# DA1470x register map
Vendor: Dialog; Series: DA1470x; File version: 1.2
CPU: CM33 r0p2, little endian, MPU, FPU, DSP, VTOR, 4 interrupt priority bits
Registers are 32-bit, read-write, reset 0x0 unless marked. A register's access mark holds for its fields unless they carry their own. Offsets are from the block's base; [hi:lo] are bit positions; {n}, {i} and the like mark numbered series.

## I3C — I3C registers
Base 0x50020C00
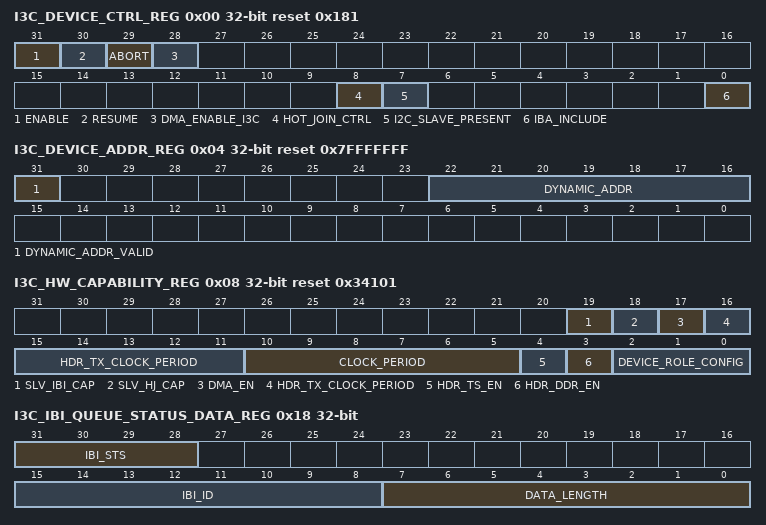
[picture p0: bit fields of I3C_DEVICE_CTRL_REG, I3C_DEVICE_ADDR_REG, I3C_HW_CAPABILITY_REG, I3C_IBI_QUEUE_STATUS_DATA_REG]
0x00 I3C_DEVICE_CTRL_REG reset 0x181 (reset mask 0x7FFFFFFF) — Device Control Register
  [31] ENABLE — Controls whether or not DWC_mipi_i3c is enabled. 1: Enables the DWC_mipi_i3c controller. 0: Disables the DWC_mipi_i3c controller. In Master mode of operation, software can Disable DWC_mipi_i3c while it is active. However, the controller may not get Disabled immediately and will be 'Disabled' after commands in the Command queue (if any) are executed leading to a STOP condition on the bus and Master FSM is in IDLE state (as indicated by PRESENT_STATE Register).
  [30] RESUME — DWC_mipi_i3c Resume. This bit is used to resume the Controller after it goes to Halt state. In the master mode of operation the controller goes to the halt state (as indicated in PRESENT_STATE Register) due to any type of error in the transfer (the type of error is indicated by ERR_STATUS field in the RESPONSE_QUEUE_PORT register). After the controller has gone to halt state, the application has to write 1'b1 to this bit to resume the controller. This bit is auto-cleared once the controller resumes the transfers by initiating the next command.
  [29] ABORT — DWC_mipi_i3c Abort. This bit is used in master mode of operation. This bit allows the controller to relinquish the I3C Bus before completing the issued transfer. In response to an ABORT request, the controller issues the STOP condition after the complete data byte is transferred or received. This bit is auto-cleared once the transfer is aborted and controller issues a 'Transfer Abort' interrupt.
  [28] DMA_ENABLE_I3C — DMA Handshake Interface Enable. This bit is used to enable or disable the DMA Handshaking interface and is applicable to both Master and Slave mode of operation. 1: Enables the DMA handshake control to interact with external DMA. 0: The DMA handshake control has no significance.
  [8] HOT_JOIN_CTRL — Hot-Join Ack/Nack Control This bit is used in master mode of operation. This bit acts as global control to ACK/NACK the Hot-Join Request from the devices. The DWC_mipi_i3c Master will ACK/NACK the Hot-Join request from other devices connected on the I3C Bus, based on programming of this bit. 0: ACK the Hot-join request. 1: NACK and send broadcast CCC to disable Hot-join. Values: 0x0 (DISABLED): Ack Hot-Join requests 0x1 (ENABLED): Nack and auto-disable Hot-Join request
  [7] I2C_SLAVE_PRESENT — I2C Slave Present This bit is used in master mode of operation. This Bit indicates whether any Legacy I2C Devices are present in the system. In HDR mode, this field is used to select TSL over TSP in mixed bus configuration. Values: 0x0 (DISABLED): I2C Slave not present 0x1 (ENABLED): I2C Slave present
  [0] IBA_INCLUDE — I3C Broadcast Address include. This bit is used in master mode of operation. This bit is used to include I3C broadcast address (0x7E) for private transfer. Note: If I3C broadcast address is not included for the private transfers, In-band Interrupts (IBI) driven from Slaves may not win address arbitration. Hence, the IBIs will get delayed. Values: 0x0 (NOT_INCLUDED): I3C Broadcast Address is not included for Private Transfers 0x1 (INCLUDED): I3C Broadcast Address is included for Private Transfers
0x04 I3C_DEVICE_ADDR_REG reset 0x7FFFFFFF (reset mask 0x7FFFFFFF) — Device Address Register
  [31] DYNAMIC_ADDR_VALID — Dynamic Address Valid This bit is used to control whether the DYNAMIC_ADDR is valid or not. In I3C Main Master mode, the user sets this bit to 1 as it self-assigns its dynamic address. In all other operation modes, the Controller sets this bit to 1 when Main Master assigns the Dynamic address during ENTDAA or SETDASA mechanism. Values: 0x0 (INVALID): Dynamic Address is invalid 0x1 (VALID): Dynamic Address is valid
  [22:16] DYNAMIC_ADDR — Device Dynamic Address. This field is used to program the Device Dynamic Address. The Controller uses this address for I3C transfers. In Main Master mode, the user/application has to program the Dynamic Address through the Slave interface as it self-assigns its Dynamic Address. In all other modes, the Main Master assigns this address during ENTDAA or SETDASA mechanism.
0x08 I3C_HW_CAPABILITY_REG reset 0x34101 — Hardware Capability register
  [19] SLV_IBI_CAP ro — Reflects the IC_SLV_IBI Configurable Parameter. Specifies slave's capability to initiate slave interrupt requests.
  [18] SLV_HJ_CAP ro — Reflects the IC_SLV_HJ Configurable Parameter. Specifies slave's capability to initiate Hot-join request.
  [17] DMA_EN ro — Reflects the IC_HAS_DMA Configurable Parameter. Specifies whether controller is configured to have DMA handshaking interface.
  [16:11] HDR_TX_CLOCK_PERIOD ro — Reflects the IC_HDR_TX_CLK_PERIOD Configurable Parameter.
  [10:5] CLOCK_PERIOD ro — Reflects the IC_CLK_PERIOD Configurable Parameter
  [4] HDR_TS_EN ro — Reflects the IC_SPEED_HDR_TS Configurable Parameter. Specifies the Controllers capability to perform HDR-TS transfers. 0 : HDR-TS not supported 1 : HDR-TS supported
  [3] HDR_DDR_EN ro — Reflects the IC_SPEED_HDR_DDR Configurable Parameter. Specifies the Controllers capability to perform HDR-DDR transfers. 0 : HDR-DDR not supported 1 : HDR-DDR supported
  [2:0] DEVICE_ROLE_CONFIG ro — Reflects the IC_DEVICE_ROLE Configurable Parameter. Specifies the configured role of DWC_mipi_i3c controller 1 : Master Only 2 : Programmable Master-Slave 3 : Secondary Master 4 : Slave Only
0x0C I3C_COMMAND_QUEUE_PORT_REG (reset mask 0x7FFFFFFF) — COMMAND_QUEUE_PORT
  [31:0] COMMAND wo — 32 bit command
0x10 I3C_RESPONSE_QUEUE_PORT_REG (reset mask 0x7FFFFFFF) — RESPONSE_QUEUE_PORT
  [31:0] RESPONSE ro — 32 bit Response
0x14 I3C_RX_TX_DATA_PORT_REG (reset mask 0x7FFFFFFF) — Receive and Transmit Data Port Register
  [31:0] RX_TX_DATA_PORT — Receive and Transmit Data Port. (Merged in Doxbox) The Receive data port is mapped to the Rx-Data Buffer. The Receive data is always packed in 4-byte aligned data words and stored in the Rx-Data Buffer. If the command length is not aligned to the 4-bytes, then the additional data bytes have to be ignored.
0x18 I3C_IBI_QUEUE_STATUS_DATA_REG (reset mask 0x7FFFFFFF) — In-Band Interrupt Queue Status and Data Register
  [31:28] IBI_STS ro — IBI Received Status. Defines the master response for IBI received. 4'b0xxx: Responded with ACK 4'b1xxx: Responded with NACK Others : RESERVED
  [15:8] IBI_ID ro — IBI Identifier. The byte received after START which includes the address and the R/W bit. Device address and R/W bit in case of Slave Interrupt or Master Request. Hot-Join ID and R/W bit in case of Hot-Join IBI.
  [7:0] DATA_LENGTH ro — In-Band Interrupt data length. This field represents the length of data received along with the IBI, in bytes.
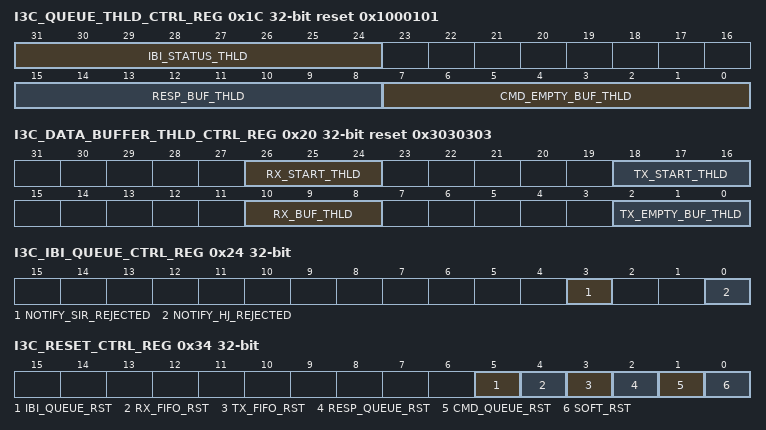
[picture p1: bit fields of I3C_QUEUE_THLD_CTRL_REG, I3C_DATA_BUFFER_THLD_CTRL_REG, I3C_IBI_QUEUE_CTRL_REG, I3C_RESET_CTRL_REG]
0x1C I3C_QUEUE_THLD_CTRL_REG reset 0x1000101 (reset mask 0x7FFFFFFF) — Queue Threshold Control Register
  [31:24] IBI_STATUS_THLD — In-Band Interrupt Status Threshold Value. Every In Band Interrupt received (with or without data) by I3C controller generates an IBI status. This field controls the number of IBI status entries (or greater) in the IBI queue that trigger the IBI_THLD_STAT interrupt. The valid range is 0 to 7. The software shall program only valid values. A value of 0 sets the threshold for 1 entry, and a value of N sets the threshold for N+1 entries.
  [15:8] RESP_BUF_THLD — Response Buffer Threshold Value. Controls the number of entries (or greater) in the Response Queue that trigger the RESP_READY_STAT_INTR interrupt. The valid range is 0 to 3. The software shall program only valid values. A value of 0 sets the threshold for 1 entry, and a value of N sets the threshold for N+1 entries.
  [7:0] CMD_EMPTY_BUF_THLD — Command Buffer Empty Threshold Value. Controls the number of empty locations (or greater) in the Command Queue that trigger CMD_QUEUE_READY_STAT interrupt. The valid range is 0 to 7. The software shall program only valid values. Value of N ranging from 1 to 7 sets the threshold to N empty locations and a value of 0 sets the threshold to indicate that the queue is completely empty.
0x20 I3C_DATA_BUFFER_THLD_CTRL_REG reset 0x3030303 — Data Buffer Threshold Control Register
  [26:24] RX_START_THLD — Receive Start Threshold Value. In master mode of operation when the controller is set up to initiate a read transfer, it waits until either one of the conditions are met before it initiates the read transfer on the I3C Interface. Data length (as specified in the command) number of locations are empty in the Receive FIFO. Threshold number of locations (or more) are empty in the Receive FIFO. The supported values for RX_START_THLD are: 000 - 1 001 - 4 010 - 8 011 - 16 100 - 32 101 - 64
  [18:16] TX_START_THLD — Transfer Start Threshold Value. In master mode of operation when the controller is set up to initiate a write transfer, it waits until either one of the following conditions are met before it initiates the write transfer on the I3C Interface. Data length (as specified in the command) number of locations are filled in the Transmit FIFO Threshold number of entries (or more) are available in the Transmit FIFO The supported values for TX_START_THLD are: 000: 1 001: 4 010: 8 011: 16 100: 32 101: 64
  [10:8] RX_BUF_THLD — Receive Buffer Threshold Value. This field controls the number of entries (or above) in the Receive FIFO that trigger the RX_THLD_STAT interrupt. If the programmed value is greater than the buffer depth, then threshold will be set to 32. The supported values for RX_BUF_THLD are 000: 1 001: 4 010: 8 011: 16 100: 32 101: 64
  [2:0] TX_EMPTY_BUF_THLD — Transmit Buffer Threshold Value. This field controls the number of empty locations (or above) in the Transmit FIFO that trigger the TX_THLD_STAT interrupt. If the programmed value is greater than the buffer depth, then threshold will be set to 32. The supported values for TX_BUF_THLD are 000: 1 001: 4 010: 8 011: 16 100: 32 101: 64
0x24 I3C_IBI_QUEUE_CTRL_REG — IBI Queue Control Register
  [3] NOTIFY_SIR_REJECTED — Notify Rejected Slave Interrupt Request Control. This bit is used to suppress reporting to the application about SIR request rejected. 0: Suppress passing the IBI Status to the IBI FIFO (hence not notifying the application) when a Slave Interrupt Request is NACKed and auto-disabled based on the IBI_SIR_REQ_REJECT Register. 1: Writes IBI Status to the IBI FIFO (hence notifying the application) when a Slave Interrupt Request is NACKed and auto-disabled based on the IBI_SIR_REQ_REJECT Register. Values: 0x0 (DISABLED): Notify SIR Rejected Disable 0x1 (ENABLED): Notify SIR Rejected Enable
  [0] NOTIFY_HJ_REJECTED — Notify Rejected Hot-Join Control. This bit is used to suppress reporting to the application about Hot-Join request rejected (NACK and Auto Disable). 0: Suppress passing the IBI Status to the IBI FIFO (hence not notifying the application) when a HJ Request is NACKed and auto-disabled based on the DEVICE_CTRL.HOT_JOIN_CTRL. 1: Writes IBI Status to the IBI FIFO (hence notifying the application) when a HJ Request is NACKed and auto-disabled based on the DEVICE_CTRL.HOT_JOIN_CTRL. Values: 0x0 (DISABLED): Notify Hot-Join Rejected Disable 0x1 (ENABLED): Notify Hot-Join Rejected Enable
0x30 I3C_IBI_SIR_REQ_REJECT_REG (reset mask 0x7FFFFFFF) — IBI SIR Request Rejection Control Register
  [31:0] SIR_REQ_REJECT — In-band Slave Interrupt Request Reject. The application of the DWC_mipi_i3c can decide whether to send ACK or NACK for a Slave request received from any I3C device. A device specific response control bit is provided to select the response option. Master will ACK/NACK the Master Request based on programming of control bit, corresponding to the interrupting device. 0 - ACK the SIR Request 1 - NACK and send directed auto disable CCC
0x34 I3C_RESET_CTRL_REG — Reset Control Register
  [5] IBI_QUEUE_RST — IBI Queue Software Reset. This bit is only used in master mode of operation. Write 1'b1 to this bit to exercise IBI Queue reset This bit will be cleared automatically once the IBI Queue reset is completed.
  [4] RX_FIFO_RST — Receive Buffer Software Reset. Write 1'b1 to this bit to exercise Receive Buffer reset. This bit will be cleared automatically once the Receive buffer reset is completed.
  [3] TX_FIFO_RST — Transmit Buffer Software Reset. Write 1'b1 to this bit to exercise Transmit Buffer reset. This bit will be cleared automatically once the Transmit Buffer reset is completed.
  [2] RESP_QUEUE_RST — Response Queue Software Reset. Write 1'b1 to this bit to exercise Response Queue reset. This bit will be cleared automatically once the Response Queue reset is completed.
  [1] CMD_QUEUE_RST — Command Queue Software Reset. Write 1'b1 to this bit to exercise Command Queue reset. This bit will the cleared automatically once the Command Queue reset is completed.
  [0] SOFT_RST — Core Software Reset. Write 1'b1 to this bit to exercise software reset. This will reset all Buffers - Receive, Transmit, Command and Response This bit will be cleared automatically once the core reset is completed.
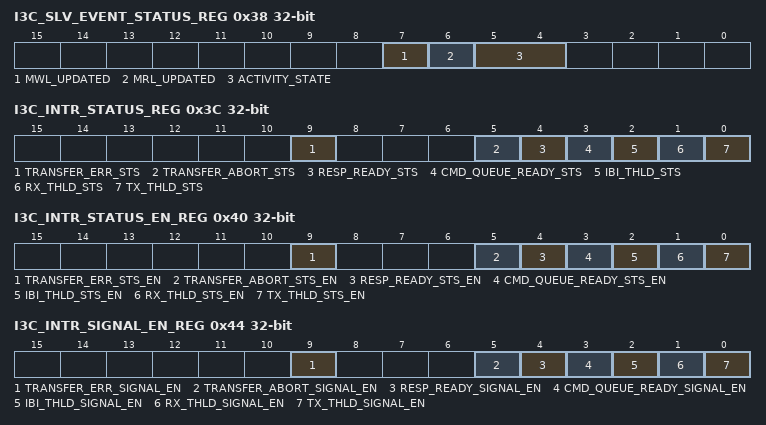
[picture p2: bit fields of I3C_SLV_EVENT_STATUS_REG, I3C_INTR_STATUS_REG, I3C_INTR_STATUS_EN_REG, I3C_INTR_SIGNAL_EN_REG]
0x38 I3C_SLV_EVENT_STATUS_REG — Slave Event Status Register
  [7] MWL_UPDATED — MWL Updated Status. This bit indicates a SETMWL CCC is received by the slave. The updated MWL value can be read from SLV_MAX_LEN register. This status can be cleared by writing 1'b1 to this field after reading the updated MWL.
  [6] MRL_UPDATED — MRL Updated Status. This bit indicates a SETMRL CCC is received by the slave. The updated MRL value can be read from SLV_MAX_LEN register. This status can be cleared by writing 1'b1 to this field after reading the updated MRL.
  [5:4] ACTIVITY_STATE ro — Activity State Status. ENTAS0 - 00 ENTAS1 - 01 ENTAS2 - 10 ENTAS3 - 11 This bit reflects the Activity State of slave set by the Master.
0x3C I3C_INTR_STATUS_REG — Interrupt Status Register
  [9] TRANSFER_ERR_STS — Transfer Error Status. This interrupt is generated if any error occurs during transfer. The error type will be specified in the response packet associated with the command (in ERR_STATUS field of RESPONSE_QUEUE_PORT register). This bit can be cleared by writing 1'b1.
  [5] TRANSFER_ABORT_STS — Transfer Abort Status. This field is used only in master mode of operation. This interrupt is generated if transfer is aborted. This interrupt can be cleared by writing 1'b1.
  [4] RESP_READY_STS ro — Response Queue Ready Status. This interrupt is generated when number of entries in response queue is greater than or equal to threshold value specified by RESP_BUF_THLD field in QUEUE_THLD_CTRL register. This interrupt will be cleared automatically when number of entries in response buffer is less than threshold value specified.
  [3] CMD_QUEUE_READY_STS ro — Command Queue Ready. This interrupt is generated when number of empty locations in command queue is greater than or equal to threshold value specified by CMD_EMPTY_BUF_THLD field in QUEUE_THLD_CTRL register. This interrupt will be cleared automatically when number of empty locations in command buffer is less than threshold value specified.
  [2] IBI_THLD_STS ro — IBI Buffer Threshold Status. This field is only used in master mode of operation This interrupt is generated when number of entries in IBI buffer is greater than or equal to threshold value specified by IBI_BUF_THLD field in QUEUE_THLD_CTRL register. This interrupt will be cleared automatically when number of entries in IBI buffer is less than threshold value specified.
  [1] RX_THLD_STS ro — Receive Buffer Threshold Status. This interrupt is generated when number of entries in receive buffer is greater than or equal to threshold value specified by RX_BUF_THLD field in DATA_BUFFER_THLD_CTRL register. This interrupt will be cleared automatically when number of entries in receive buffer is less than threshold value specified.
  [0] TX_THLD_STS ro — Transmit Buffer Threshold Status. This interrupt is generated when number of empty locations in transmit buffer is greater than or equal to threshold value specified by TX_EMPTY_BUF_THLD field in DATA_BUFFER_THLD_CTRL register. This interrupt will be cleared automatically when number of empty locations in transmit buffer is less than threshold value specified.
0x40 I3C_INTR_STATUS_EN_REG — Interrupt Status Enable Register
  [9] TRANSFER_ERR_STS_EN — Transfer Error Status Enable
  [5] TRANSFER_ABORT_STS_EN — Transfer Abort Status Enable. This field is used only in master mode of operation.
  [4] RESP_READY_STS_EN — Response Queue Ready Status Enable
  [3] CMD_QUEUE_READY_STS_EN — Command Queue Ready Status Enable
  [2] IBI_THLD_STS_EN — IBI Buffer Threshold Status Enable. This field is used only in master mode of operation.
  [1] RX_THLD_STS_EN — Receive Buffer Threshold Status Enable
  [0] TX_THLD_STS_EN — Transmit Buffer Threshold Status Enable
0x44 I3C_INTR_SIGNAL_EN_REG — Interrupt Signal Enable Register
  [9] TRANSFER_ERR_SIGNAL_EN — Transfer Error Signal Enable
  [5] TRANSFER_ABORT_SIGNAL_EN — Transfer Abort Signal Enable. This field is used only in master mode of operation.
  [4] RESP_READY_SIGNAL_EN — Response Queue Ready Signal Enable
  [3] CMD_QUEUE_READY_SIGNAL_EN — Command Queue Ready Signal Enable
  [2] IBI_THLD_SIGNAL_EN — IBI Buffer Threshold Signal Enable. This field is used only in master mode of operation.
  [1] RX_THLD_SIGNAL_EN — Receive Buffer Threshold Signal Enable
  [0] TX_THLD_SIGNAL_EN — Transmit Buffer Threshold Signal Enable. *Note: For the deassertion of the interrupt, first the *SIGNAL_EN bitfield should be cleared and then the *STATUS_EN one, otherwise is not working. This comment applies for the rest bitfields of this register
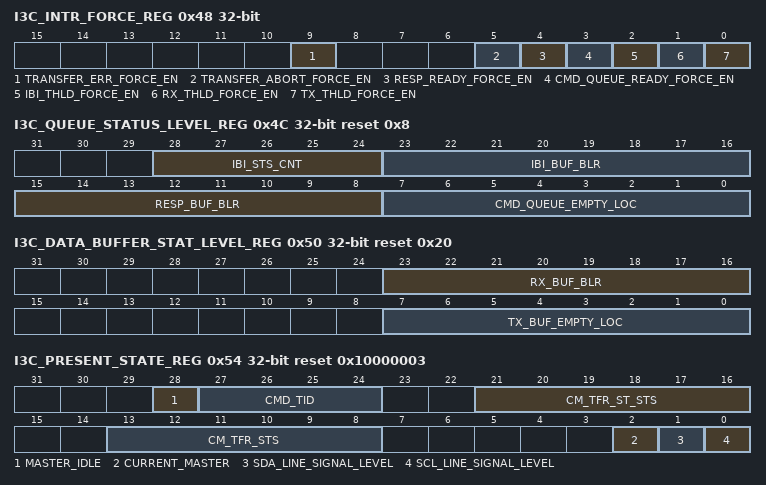
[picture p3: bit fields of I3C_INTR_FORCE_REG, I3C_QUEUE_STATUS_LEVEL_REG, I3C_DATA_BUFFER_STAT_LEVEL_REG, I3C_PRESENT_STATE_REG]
0x48 I3C_INTR_FORCE_REG — Interrupt Force Enable Register
  [9] TRANSFER_ERR_FORCE_EN wo — Transfer Error Force Enable
  [5] TRANSFER_ABORT_FORCE_EN wo — Transfer Abort Force Enable. This field is used only in master mode of operation.
  [4] RESP_READY_FORCE_EN wo — Response Queue Ready Force Enable
  [3] CMD_QUEUE_READY_FORCE_EN wo — Command Queue Ready Force Enable
  [2] IBI_THLD_FORCE_EN wo — IBI Buffer Threshold Force Enable. This field is used only in master mode of operation.
  [1] RX_THLD_FORCE_EN wo — Receive Buffer Threshold Force Enable
  [0] TX_THLD_FORCE_EN wo — Transmit Buffer Threshold Force Enable.
0x4C I3C_QUEUE_STATUS_LEVEL_REG reset 0x8 — Queue Status Level Register
  [28:24] IBI_STS_CNT ro — IBI Buffer Status Count. Contains the number of IBI status entries in the IBI Buffer. This field is used in master mode of operation.
  [23:16] IBI_BUF_BLR ro — IBI Buffer Level Value. Contains the number of valid entries in the IBI Buffer. This field is used in master mode of operation.
  [15:8] RESP_BUF_BLR ro — Response Buffer Level Value. Contains the number of valid data entries in the response Buffer.
  [7:0] CMD_QUEUE_EMPTY_LOC ro — Command Queue Empty Locations. Contains the number of empty locations in the command Buffer.
0x50 I3C_DATA_BUFFER_STAT_LEVEL_REG reset 0x20 — Data Buffer Status Level Register
  [23:16] RX_BUF_BLR ro — Receive Buffer Level Value. Contains the number of valid data entries in the receive Buffer.
  [7:0] TX_BUF_EMPTY_LOC ro — Transmit Buffer Empty Level Value. Contains the number of empty locations in the transmit Buffer.
0x54 I3C_PRESENT_STATE_REG reset 0x10000003 — Present State Register
  [28] MASTER_IDLE ro — This field reflects whether the Master Controller is in Idle state or not. This bit will set when all the Queues(Command , Response, IBI) and Buffers(Transmit and Receive) are empty along with the Master State machine is in Idle state. Values: 0x0 (MST_NOT_IDLE): Master Controller is not in IDLE State 0x1 (MST_IDLE): Master Controller is in IDLE State.
  [27:24] CMD_TID ro — This field reflects the Transaction-ID of the current executing command.
  [21:16] CM_TFR_ST_STS ro — Current Master Transfer State Status. Indicates the state of current transfer currently executing by the DWC_mipi_i3c controller. This is valid in Master mode only. 6'h0: IDLE (Controller is Idle state, waiting for commands from application or Slave initated In-band Interrupt) 6'h1: START Generation State. 6'h2: RESTART Generation State. 6'h3: STOP Generation State. 6'h4: START Hold Generation for the Slave Initiated START State. 6'h5: Broadcast Write Address Header(7'h7E,W) Generation State. 6'h6: Broadcast Read Address Header(7'h7E,R) Generation State. 6'h7: Dynamic Address Assignment State. 6'h8: Slave Address Generation State. 6'hB: CCC Byte Generation State. 6'hC: HDR Command Generation State. 6'hD: Write Data Transfer State. 6'hE: Read Data Transfer State. 6'hF: In-Band Interrupt(SIR) Read Data State. 6'h10: In-Band Interrupt Auto-Disable State 6'h11: HDR-DDR CRC Data Generation/Receive State. 6'h12: Clock Extension State. 6'h13: Halt State.
  [13:8] CM_TFR_STS ro — Transfer Type Status. Indicates the type of transfer currently executing by the DWC_mipi_i3c controller. In Master mode of operation : 6'h0: IDLE (Controller is in Idle state, waiting for commands from application or Slave initated In-band Interrupt) 6'h1: Broadcast CCC Write Transfer. 6'h2: Directed CCC Write Transfer. 6'h3: Directed CCC Read Transfer. 6'h4: ENTDAA Address Assignment Transfer. 6'h5: SETDASA Address Assignment Transfer. 6'h6: Private I3C SDR Write Transfer. 6'h7: Private I3C SDR Read Transfer. 6'h8: Private I2C SDR Write Transfer. 6'h9: Private I2C SDR Read Transfer. 6'hA: Private HDR Ternary Symbol(TS) Write Transfer. 6'hB: Private HDR Ternary Symbol(TS) Read Transfer. 6'hC: Private HDR Double-Data Rate(DDR) Write Transfer. 6'hD: Private HDR Double-Data Rate(DDR) Read Transfer. 6'hE: Servicing In-Band Interrupt Transfer. 6'hF: Halt state (Controller is in Halt State, waiting for the application to resume through DEVICE_CTRL Register)
  [2] CURRENT_MASTER ro — This Bit is used to check whether the Master is Current Master or not. The Current Master is the Master that owns the SCL line. If this bit is set to 0, the Master is not Current Master and requires to request and the ownership before initiating any transfer on the line. If this bit is set to 1, the Master is the Current Master and can initate the transfers on the line. 0: Master is not Current Master 1: Master is Current Master
  [1] SDA_LINE_SIGNAL_LEVEL ro — This bit is used to check the SDA line level to recover from errors and for debugging. This bit reflects the value of synchronized sda_in_a signal. This is valid in Master mode only.
  [0] SCL_LINE_SIGNAL_LEVEL ro — This bit is used to check the SCL line level to recover from errors and for debugging. This bit reflects the value of synchronized scl_in_a signal. This is valid in Master mode only
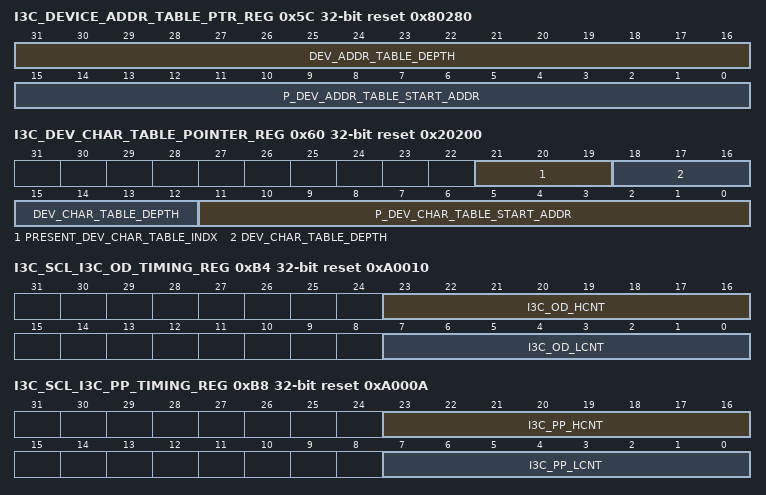
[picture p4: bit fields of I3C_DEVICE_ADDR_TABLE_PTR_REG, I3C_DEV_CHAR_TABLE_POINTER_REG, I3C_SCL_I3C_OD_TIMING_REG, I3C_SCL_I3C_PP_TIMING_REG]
0x5C I3C_DEVICE_ADDR_TABLE_PTR_REG reset 0x80280 (reset mask 0x7FFFFFFF) — Pointer for Device Address Table Registers
  [31:16] DEV_ADDR_TABLE_DEPTH ro — Depth of Device Address Table
  [15:0] P_DEV_ADDR_TABLE_START_ADDR ro — Start Address of Device Address Table.
0x60 I3C_DEV_CHAR_TABLE_POINTER_REG reset 0x20200 — Pointer for Device Characteristics Table
  [21:19] PRESENT_DEV_CHAR_TABLE_INDX — Current index of Device Characteristics Table. This field returns the current location of Device Characteristics Table index. Initially, this index points to 0. Once the complete characteristics information of a Slave device is written into Device Characteristics Table during ENTDAA, this index increments by 1. The first winning device information is stored in Device Characteristics Table index 0, the second winning device information in index 1, and so on. If required, this index can be used to override the location, where characteristic information of Slave devices on the I3C bus are written during ENTDAA. Hence, this field is useful only if the device is Current Master. During DEFSLV CCC, the index always starts from 0. In Non-current Master, this field is always read-only.
  [18:12] DEV_CHAR_TABLE_DEPTH ro — Depth of Device Characteristics Table
  [11:0] P_DEV_CHAR_TABLE_START_ADDR ro — Start Address of Device Characteristics Table.
0x6C I3C_VENDOR_SPECIFIC_REG_PTR_REG reset 0xB0 — Pointer for Vendor specific Registers
  [15:0] P_VENDOR_REG_START_ADDR ro — Start Address of Vendor specific registers.
0xB0 I3C_DEVICE_CTRL_EXTENDED_REG — Device Control Extended Register
  [1:0] DEV_OPERATION_MODE — This bit is used to select the Device Operation Mode before the controller is enabled. This field shall be written only when the DWC_mipi_i3c is disabled. 0: Master 1: Slave 2: Reserved 3: Reserved This field will be automatically updated by the controller once the role change happens in secondary master mode..
0xB4 I3C_SCL_I3C_OD_TIMING_REG reset 0xA0010 — SCL I3C Open Drain Timing Register
  [23:16] I3C_OD_HCNT — I3C Open Drain High Count. SCL open-drain High count (I3C) for I3C transfers targeted to I3C devices.
  [7:0] I3C_OD_LCNT — I3C Open Drain Low Count. SCL Open-drain low count for I3C transfers targeted to I3C devices.
0xB8 I3C_SCL_I3C_PP_TIMING_REG reset 0xA000A — SCL I3C Push Pull Timing Register
  [23:16] I3C_PP_HCNT — I3C Push Pull High Count. SCL push-pull High count for I3C transfers targeted to I3C devices.
  [7:0] I3C_PP_LCNT — I3C Push Pull Low Count. SCL Push-pull low count for I3C transfers targeted to I3C devices.
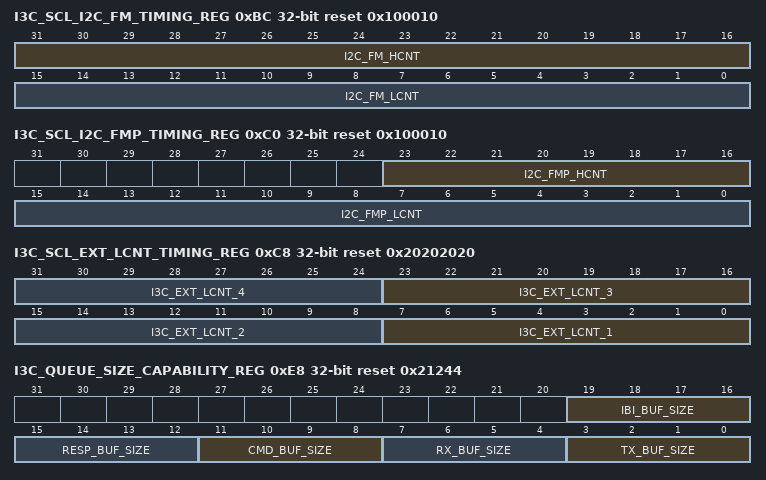
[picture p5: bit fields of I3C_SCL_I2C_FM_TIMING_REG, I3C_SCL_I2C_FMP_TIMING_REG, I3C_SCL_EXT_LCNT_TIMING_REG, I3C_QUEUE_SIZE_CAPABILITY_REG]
0xBC I3C_SCL_I2C_FM_TIMING_REG reset 0x100010 (reset mask 0x7FFFFFFF) — SCL I2C Fast Mode Timing Register
  [31:16] I2C_FM_HCNT — I2C Fast Mode High Count The SCL open-drain high count timing for I2C fast mode transfers.
  [15:0] I2C_FM_LCNT — I2C Fast Mode Low Count The SCL open-drain low count timing for I2C fast mode transfers.
0xC0 I3C_SCL_I2C_FMP_TIMING_REG reset 0x100010 — SCL I2C Fast Mode Plus Timing Register
  [23:16] I2C_FMP_HCNT — I2C Fast Mode Plus High Count The SCL open-drain high count timing for I2C fast mode transfers.
  [15:0] I2C_FMP_LCNT — I2C Fast Mode Plus Low Count The SCL open-drain low count timing for I2C fast mode transfers.
0xC8 I3C_SCL_EXT_LCNT_TIMING_REG reset 0x20202020 (reset mask 0x7FFFFFFF) — SCL Extended Low Count Timing Register
  [8n-1:8n-8] I3C_EXT_LCNT_{n} (n=1..4) — I3C Extended Low Count Register {n} SDR{n} uses this register field for data transfer.
0xCC I3C_SCL_EXT_TERMN_LCNT_TIME_REG — SCL Termination Bit Low count Timing Register
  [3:0] I3C_EXT_TERMN_LCNT — I3C Read Termination Bit Low count. Extended I3C Read Termination Bit low count for I3C Read transfers. Effective Termination-Bit Low Period is derived based on the SDR speed as shown below SDR0 speed: I3C_PP_LCNT + I3C_EXT_TERMN_LCNT SDR1 speed: I3C_EXT_LCNT_1 + I3C_EXT_TERMN_LCNT SDR2 speed: I3C_EXT_LCNT_2 + I3C_EXT_TERMN_LCNT SDR3 speed: I3C_EXT_LCNT_3 + I3C_EXT_TERMN_LCNT SDR4 speed: I3C_EXT_LCNT_4 + I3C_EXT_TERMN_LCNT
0xD0 I3C_SDA_HOLD_DLY_TIMING_REG reset 0x10000 — SDA Hold Delay Timing Register
  [18:16] SDA_TX_HOLD — This field controls the hold time (in term of the core clock period) of the transmit data (SDA) with respect to the SCL edge in FM FM+ SDR and DDR speed mode of operations. This field is not applicable for the ternary speed modes. The valid values are 1 to 7. Others are Reserved.
0xD4 I3C_BUS_FREE_AVAIL_TIMING_REG reset 0x20 — Bus Free Timing Register
  [15:0] BUS_FREE_TIME — This register field is used only in Master mode of operation I3C Bus Free Count Value. In Pure Bus System, this field represents tCAS parameter. In Mixed Bus system, this field is expected to be programmed to tLOW of I2C Timing.
0xE0 I3C_VER_ID_REG reset 0x3130302A (reset mask 0x7FFFFFFF) — DWC_mipi_i3c Version ID Register
  [31:0] I3C_VER_ID ro — Current release type This field indicates the Synopsys DesignWare Cores DWC_mipi_i3c current release type that is read by an application. For example, release type "ga" is represented in ASCII as 0x6761 and "ea" is represented as 0x6561. Lower 16 bits read from this register can be ignored by the application if release type is "ga". If release type is "ea" the lower 16 bits represents the "ea" release version. An application reading this register along with the I3C_VER_ID register, gathers details of the current release.
0xE4 I3C_VER_TYPE_REG reset 0x6C633033 (reset mask 0x7FFFFFFF) — DWC_mipi_i3c Version Type Register
  [31:0] I3C_VER_TYPE ro — Current release type This field indicates the Synopsys DesignWare Cores DWC_mipi_i3c current release type that is read by an application. For example, release type "ga" is represented in ASCII as 0x6761 and "ea" is represented as 0x6561. Lower 16 bits read from this register can be ignored by the application if release type is "ga". If release type is "ea" the lower 16 bits represents the "ea" release version. An application reading this register along with the I3C_VER_ID register, gathers details of the current release.
0xE8 I3C_QUEUE_SIZE_CAPABILITY_REG reset 0x21244 — DWC_mipi_i3c Queue Size Capability Register
  [19:16] IBI_BUF_SIZE ro — IBI Queue Size This field reflects the configured IBI Queue size (in DWORDS) in Encoded Values. Values: - 0x0 : 2 DWORDS - 0x1 : 4 DWORDS - 0x2 : 8 DWORDS - 0x3 : 16 DWORDS
  [15:12] RESP_BUF_SIZE ro — Response Queue Size This field reflects the configured Response Queue size (in DWORDS) in Encoded Values. Values: - 0x0 : 2 DWORDS - 0x1 : 4 DWORDS - 0x2 : 8 DWORDS - 0x3 : 16 DWORDS
  [11:8] CMD_BUF_SIZE ro — Command Queue Size This field reflects the configured Command Queue size (in DWORDS) in Encoded Values. Values: - 0x0 : 2 DWORDS - 0x1 : 4 DWORDS - 0x2 : 8 DWORDS - 0x3 : 16 DWORDS
  [7:4] RX_BUF_SIZE ro — Receive Data Buffer Size This field reflects the configured Receive Buffer size (in DWORDS) in Encoded Values. Values: - 0x0 : 2 DWORDS - 0x1 : 4 DWORDS - 0x2 : 8 DWORDS - 0x3 : 16 DWORDS - 0x4 : 32 DWORDS - 0x5 : 64 DWORDS
  [3:0] TX_BUF_SIZE ro — Transmit Data Buffer Size This field reflects the configured Transmit Buffer size (in DWORDS) in Encoded Values. Values: - 0x0 : 2 DWORDS - 0x1 : 4 DWORDS - 0x2 : 8 DWORDS - 0x3 : 16 DWORDS - 0x4 : 32 DWORDS - 0x5 : 64 DWORDS
{0x1F0+0x10*i} I3C_DEV_CHAR_TABLE{i}_LOC1_REG (reset mask 0x7FFFFFFF) (i=1..8) — Device Characteristic Table Location-1 of Device{i}
  [31:0] LSB_PROVISIONAL_ID ro — The LSB 32-bit value of Provisional-ID
{0x1F4+0x10*i} I3C_DEV_CHAR_TABLE{i}_LOC2_REG (i=1..8) — Device Characteristic Table Location-2 of Device{i}
  [15:0] MSB_PROVISIONAL_ID ro — The MSB 16-bit value of Provisional-ID
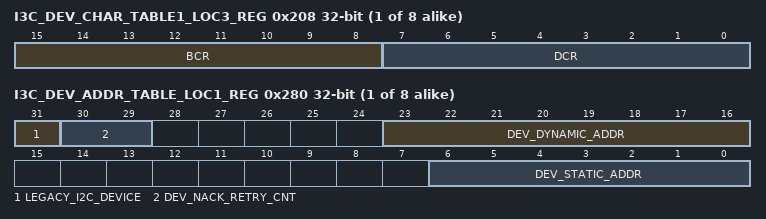
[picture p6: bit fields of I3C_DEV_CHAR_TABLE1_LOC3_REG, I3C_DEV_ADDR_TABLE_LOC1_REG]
{0x1F8+0x10*i} I3C_DEV_CHAR_TABLE{i}_LOC3_REG (i=1..8) — Device Characteristic Table Location-3 of Device{i}
  [15:8] BCR ro — Bus Characteristic Value
  [7:0] DCR ro — Device Characteristic Value
{0x1FC+0x10*i} I3C_DEV_CHAR_TABLE{i}_LOC4_REG (i=1..8) — Device Characteristic Table Location-4 of Device{i}
  [7:0] DEV_DYNAMIC_ADDR_LOC4 ro — Device Dynamic Address assigned.
{0x27C+4i} I3C_DEV_ADDR_TABLE_LOC{i}_REG (reset mask 0x7FFFFFFF) (i=1..8) — Device Address Table of Device{i}
  [31] LEGACY_I2C_DEVICE — Legacy I2C device or not. This bit should be set to 1 if the device is a legacy I2C device.
  [30:29] DEV_NACK_RETRY_CNT — This field is used to set the Device NACK Retry count for the particular device. If the Device NACK's for the device address, the controller automatically retries the same device until this count expires. If the Slave does not ACK for the mentioned number of retries, then Controller generates an error response and move to the Halt state. This feature is used for Retry Model for the following features mentioned in the I3C Specification: Retry Model for Direct GET CCC Commands. The incoming SIR-IBI matches with the slave address initated by the Master.
  [23:16] DEV_DYNAMIC_ADDR — Device Dynamic Address with parity. The MSB, bit[23], should be programmed with parity of dynamic address.
  [6:0] DEV_STATIC_ADDR — Device Static Address.
